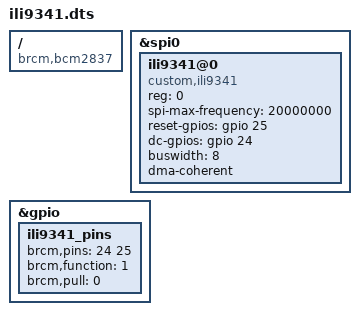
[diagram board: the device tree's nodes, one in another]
/dts-v1/;
/plugin/;

/ {
    compatible = "brcm,bcm2837";

    fragment@0 {
        target = <&spi0>;
        __overlay__ {
            status = "okay";
            #address-cells = <1>;
            #size-cells = <0>;

            ili9341@0 {
                compatible = "custom,ili9341";
                reg = <0>;
                spi-max-frequency = <20000000>;
                reset-gpios = <&gpio 25 0>;  /* GPIO25 for RST */
                dc-gpios = <&gpio 24 0>;     /* GPIO24 for DC */
                buswidth = <8>;

                // Required if you need DMA
                dma-coherent;

                status = "okay";
            };
        };
    };

    fragment@1 {
        target = <&gpio>;
        __overlay__ {
            ili9341_pins: ili9341_pins {
                brcm,pins = <24 25>;  /* GPIO24 (DC) and GPIO25 (RST) */
                brcm,function = <1>;  /* Output */
                brcm,pull = <0>;      /* No pull */
            };
        };
    };
}; 
